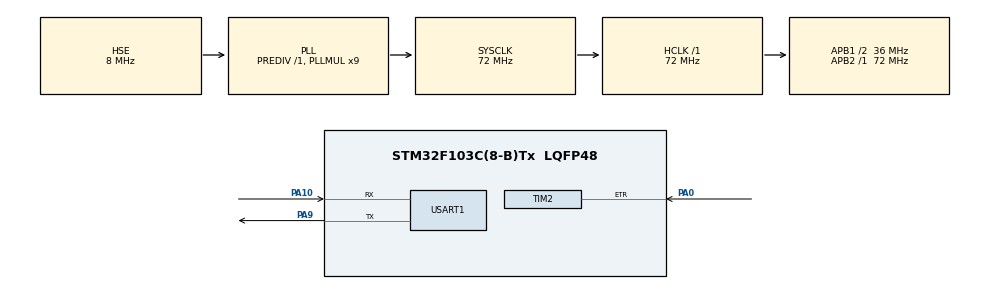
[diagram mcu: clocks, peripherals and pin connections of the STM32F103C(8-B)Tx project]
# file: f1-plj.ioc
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Mcu.Family=STM32F1
Mcu.Name=STM32F103C(8-B)Tx
Mcu.Package=LQFP48
NVIC.PriorityGroup=NVIC_PRIORITYGROUP_4
NVIC.TIM2_IRQn=true\:0\:0\:false\:false\:true\:true\:true\:true
NVIC.TIM3_IRQn=true\:0\:0\:false\:false\:true\:true\:true\:true
NVIC.USART1_IRQn=true\:0\:0\:false\:false\:true\:true\:true\:true
PA0-WKUP.Signal=S_TIM2_CH1_ETR
PA10.Mode=Asynchronous
PA10.Signal=USART1_RX
PA9.Mode=Asynchronous
PA9.Signal=USART1_TX
PD0-OSC_IN.Mode=HSE-External-Oscillator
PD0-OSC_IN.Signal=RCC_OSC_IN
PD1-OSC_OUT.Mode=HSE-External-Oscillator
PD1-OSC_OUT.Signal=RCC_OSC_OUT
ProjectManager.HeapSize=0x200
ProjectManager.StackSize=0x400
ProjectManager.TargetToolchain=MDK-ARM V5.32
RCC.AHBFreq_Value=72000000
RCC.APB1CLKDivider=RCC_HCLK_DIV2
RCC.APB1Freq_Value=36000000
RCC.APB1TimFreq_Value=72000000
RCC.APB2Freq_Value=72000000
RCC.APB2TimFreq_Value=72000000
RCC.HCLKFreq_Value=72000000
RCC.PLLMUL=RCC_PLL_MUL9
RCC.PLLSourceVirtual=RCC_PLLSOURCE_HSE
RCC.SYSCLKFreq_VALUE=72000000
RCC.SYSCLKSource=RCC_SYSCLKSOURCE_PLLCLK
RCC.USBFreq_Value=72000000
SH.S_TIM2_CH1_ETR.0=TIM2_ETR,ClockSourceETR_Mode2
TIM2.Period=50000
TIM3.Period=50000-1
TIM3.Prescaler=720-1
USART1.VirtualMode=VM_ASYNC
VP_SYS_VS_ND.Mode=No_Debug
VP_TIM3_VS_ClockSourceINT.Mode=Internal
board=custom

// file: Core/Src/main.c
/* USER CODE BEGIN Header */
/**
  ******************************************************************************
  * @file           : main.c
  * @brief          : Main program body
  ******************************************************************************
  * @attention
  *
  * Copyright (c) 2024 STMicroelectronics.
  * All rights reserved.
  *
  * This software is licensed under terms that can be found in the LICENSE file
  * in the root directory of this software component.
  * If no LICENSE file comes with this software, it is provided AS-IS.
  *
  ******************************************************************************
  */
/* USER CODE END Header */
#include "main.h"
#include "tim.h"
#include "usart.h"
#include "gpio.h"

/* USER CODE BEGIN Includes */
#include "stdio.h"
/* USER CODE END Includes */

/* USER CODE BEGIN PV */
int time_50000,tim3_flag,timer2;
uint32_t freqency,temp_freq;
uint8_t RxData[10]={0,0,0,0,0,0,0,0,0,0};
/* USER CODE END PV */

void SystemClock_Config(void);
/* USER CODE BEGIN PFP */
#ifdef __GNUC__
#define PUTCHAR_PROTOTYPE int __io_putchar(int ch)
#else
#define PUTCHAR_PROTOTYPE int fputc(int ch, FILE *f)
#endif
PUTCHAR_PROTOTYPE
{
    //huart1
    HAL_UART_Transmit(&huart1 , (uint8_t *)&ch, 1 , 0xffff);
    return ch;
}
/* USER CODE END PFP */

int main(void)
{

  /* MCU Configuration--------------------------------------------------------*/

  /* Reset of all peripherals, Initializes the Flash interface and the Systick. */
  HAL_Init();

  /* Configure the system clock */
  SystemClock_Config();

  /* Initialize all configured peripherals */
  MX_GPIO_Init();
  MX_TIM2_Init();
  MX_TIM3_Init();
  MX_USART1_UART_Init();
  /* USER CODE BEGIN 2 */
	HAL_TIM_Base_Start_IT(&htim2);
	HAL_TIM_Base_Start_IT(&htim3);
  /* USER CODE END 2 */

  /* Infinite loop */
  while (1)
  {

  }
}

void SystemClock_Config(void)
{
  RCC_OscInitTypeDef RCC_OscInitStruct = {0};
  RCC_ClkInitTypeDef RCC_ClkInitStruct = {0};

  /** Initializes the RCC Oscillators according to the specified parameters
  * in the RCC_OscInitTypeDef structure.
  */
  RCC_OscInitStruct.OscillatorType = RCC_OSCILLATORTYPE_HSE;
  RCC_OscInitStruct.HSEState = RCC_HSE_ON;
  RCC_OscInitStruct.HSEPredivValue = RCC_HSE_PREDIV_DIV1;
  RCC_OscInitStruct.HSIState = RCC_HSI_ON;
  RCC_OscInitStruct.PLL.PLLState = RCC_PLL_ON;
  RCC_OscInitStruct.PLL.PLLSource = RCC_PLLSOURCE_HSE;
  RCC_OscInitStruct.PLL.PLLMUL = RCC_PLL_MUL9;
  if (HAL_RCC_OscConfig(&RCC_OscInitStruct) != HAL_OK)
  {
    Error_Handler();
  }

  /** Initializes the CPU, AHB and APB buses clocks
  */
  RCC_ClkInitStruct.ClockType = RCC_CLOCKTYPE_HCLK|RCC_CLOCKTYPE_SYSCLK
                              |RCC_CLOCKTYPE_PCLK1|RCC_CLOCKTYPE_PCLK2;
  RCC_ClkInitStruct.SYSCLKSource = RCC_SYSCLKSOURCE_PLLCLK;
  RCC_ClkInitStruct.AHBCLKDivider = RCC_SYSCLK_DIV1;
  RCC_ClkInitStruct.APB1CLKDivider = RCC_HCLK_DIV2;
  RCC_ClkInitStruct.APB2CLKDivider = RCC_HCLK_DIV1;

  if (HAL_RCC_ClockConfig(&RCC_ClkInitStruct, FLASH_LATENCY_2) != HAL_OK)
  {
    Error_Handler();
  }
}

/* USER CODE BEGIN 4 */
void HAL_TIM_PeriodElapsedCallback(TIM_HandleTypeDef *htim)
{
		if(htim->Instance==htim3.Instance)
		{

			//printf("cle 1,255\xff\xff\xff");
			HAL_TIM_Base_Stop_IT(&htim2);
			timer2=TIM2->CNT;
			freqency=(time_50000*50000+timer2)*2;
			time_50000=0;
			TIM2->CNT=0;
			HAL_TIM_Base_Start_IT(&htim2);
			tim3_flag=1;
			if(tim3_flag==1) printf("%8d",(int)(freqency*1.0017));
//			printf("t48.txt=\"%dHz\"\xff\xff\xff",freqency);
//			HAL_UART_Receive_IT(&huart1,RxData,8);
//			printf("%sHz\r\n",RxData);

		}
		if(htim->Instance==htim2.Instance)
		{
			time_50000++;
		}
}
/* USER CODE END 4 */

void Error_Handler(void)
{
  __disable_irq();
  while (1)
  {
  }
}
